AUTOSAR XML (schema 4-2-2)
package /STELLANTIS/EPT/ASWCs
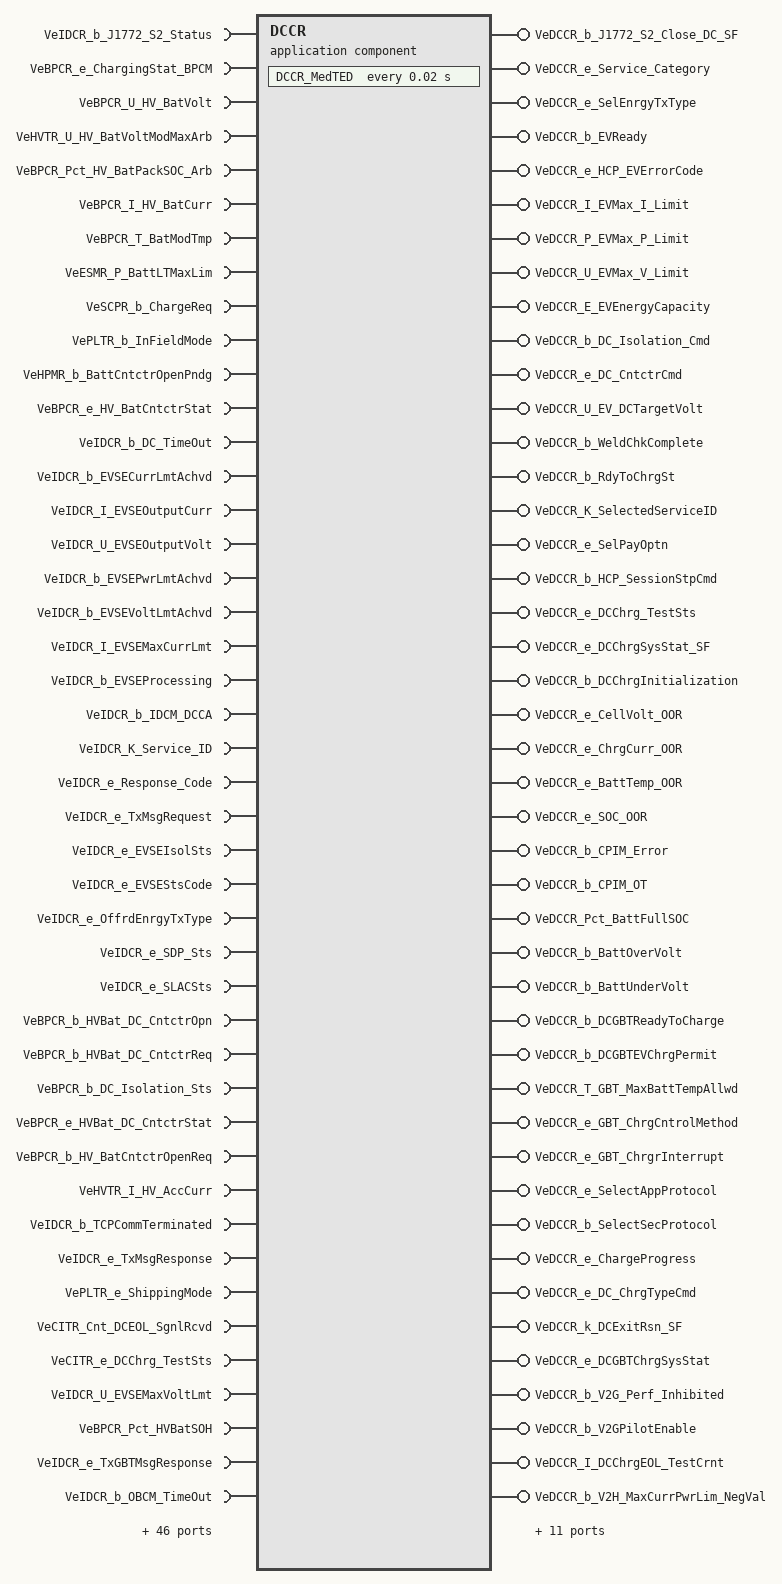
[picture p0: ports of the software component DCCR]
  application sw component type DCCR
    85 x require port:
      VeIDCR_b_J1772_S2_Status: variation-point={short-label=vpVeIDCR_b_J1772_S2_Status, sw-syscond=1}, nonqueued-receiver-com-spec{data-element=Value, init-value=0}, required-interface=VeIDCR_b_J1772_S2_Status
      VeBPCR_e_ChargingStat_BPCM: variation-point={short-label=vpVeBPCR_e_ChargingStat_BPCM, sw-syscond=1}, nonqueued-receiver-com-spec{data-element=Value, init-value=CeOBCR_e_BattNotReady}, required-interface=VeBPCR_e_ChargingStat_BPCM
      VeBPCR_U_HV_BatVolt: variation-point={short-label=vpVeBPCR_U_HV_BatVolt, sw-syscond=1}, nonqueued-receiver-com-spec{data-element=Value, init-value=0}, required-interface=VeBPCR_U_HV_BatVolt
      VeHVTR_U_HV_BatVoltModMaxArb: variation-point={short-label=vpVeHVTR_U_HV_BatVoltModMaxArb, sw-syscond=1}, nonqueued-receiver-com-spec{data-element=Value, init-value=0}, required-interface=VeHVTR_U_HV_BatVoltModMaxArb
      VeBPCR_Pct_HV_BatPackSOC_Arb: variation-point={short-label=vpVeBPCR_Pct_HV_BatPackSOC_Arb, sw-syscond=1}, nonqueued-receiver-com-spec{data-element=Value, init-value=0}, required-interface=VeBPCR_Pct_HV_BatPackSOC_Arb
      VeBPCR_I_HV_BatCurr: variation-point={short-label=vpVeBPCR_I_HV_BatCurr, sw-syscond=1}, nonqueued-receiver-com-spec{data-element=Value, init-value=0}, required-interface=VeBPCR_I_HV_BatCurr
      VeBPCR_T_BatModTmp: variation-point={short-label=vpVeBPCR_T_BatModTmp, sw-syscond=1}, nonqueued-receiver-com-spec{data-element=Value, init-value=0}, required-interface=VeBPCR_T_BatModTmp
      VeESMR_P_BattLTMaxLim: variation-point={short-label=vpVeESMR_P_BattLTMaxLim, sw-syscond=1}, nonqueued-receiver-com-spec{data-element=Value, init-value=0}, required-interface=VeESMR_P_BattLTMaxLim
      VeSCPR_b_ChargeReq: variation-point={short-label=vpVeSCPR_b_ChargeReq, sw-syscond=1}, nonqueued-receiver-com-spec{data-element=Value, init-value=0}, required-interface=VeSCPR_b_ChargeReq
      VePLTR_b_InFieldMode: variation-point={short-label=vpVePLTR_b_InFieldMode, sw-syscond=1}, nonqueued-receiver-com-spec{data-element=Value, init-value=0}, required-interface=VePLTR_b_InFieldMode
      VeHPMR_b_BattCntctrOpenPndg: variation-point={short-label=vpVeHPMR_b_BattCntctrOpenPndg, sw-syscond=1}, nonqueued-receiver-com-spec{data-element=Value, init-value=0}, required-interface=VeHPMR_b_BattCntctrOpenPndg
      VeBPCR_e_HV_BatCntctrStat: variation-point={short-label=vpVeBPCR_e_HV_BatCntctrStat, sw-syscond=1}, nonqueued-receiver-com-spec{data-element=Value, init-value=CeHVTR_e_Open}, required-interface=VeBPCR_e_HV_BatCntctrStat
      VeIDCR_b_DC_TimeOut: variation-point={short-label=vpVeIDCR_b_DC_TimeOut, sw-syscond=1}, nonqueued-receiver-com-spec{data-element=Value, init-value=0}, required-interface=VeIDCR_b_DC_TimeOut
      VeIDCR_b_EVSECurrLmtAchvd: variation-point={short-label=vpVeIDCR_b_EVSECurrLmtAchvd, sw-syscond=1}, nonqueued-receiver-com-spec{data-element=Value, init-value=0}, required-interface=VeIDCR_b_EVSECurrLmtAchvd
      VeIDCR_I_EVSEOutputCurr: variation-point={short-label=vpVeIDCR_I_EVSEOutputCurr, sw-syscond=1}, nonqueued-receiver-com-spec{data-element=Value, init-value=0}, required-interface=VeIDCR_I_EVSEOutputCurr
      VeIDCR_U_EVSEOutputVolt: variation-point={short-label=vpVeIDCR_U_EVSEOutputVolt, sw-syscond=1}, nonqueued-receiver-com-spec{data-element=Value, init-value=0}, required-interface=VeIDCR_U_EVSEOutputVolt
      VeIDCR_b_EVSEPwrLmtAchvd: variation-point={short-label=vpVeIDCR_b_EVSEPwrLmtAchvd, sw-syscond=1}, nonqueued-receiver-com-spec{data-element=Value, init-value=0}, required-interface=VeIDCR_b_EVSEPwrLmtAchvd
      VeIDCR_b_EVSEVoltLmtAchvd: variation-point={short-label=vpVeIDCR_b_EVSEVoltLmtAchvd, sw-syscond=1}, nonqueued-receiver-com-spec{data-element=Value, init-value=0}, required-interface=VeIDCR_b_EVSEVoltLmtAchvd
      VeIDCR_I_EVSEMaxCurrLmt: variation-point={short-label=vpVeIDCR_I_EVSEMaxCurrLmt, sw-syscond=1}, nonqueued-receiver-com-spec{data-element=Value, init-value=0}, required-interface=VeIDCR_I_EVSEMaxCurrLmt
      VeIDCR_b_EVSEProcessing: variation-point={short-label=vpVeIDCR_b_EVSEProcessing, sw-syscond=1}, nonqueued-receiver-com-spec{data-element=Value, init-value=0}, required-interface=VeIDCR_b_EVSEProcessing
      VeIDCR_b_IDCM_DCCA: variation-point={short-label=vpVeIDCR_b_IDCM_DCCA, sw-syscond=1}, nonqueued-receiver-com-spec{data-element=Value, init-value=0}, required-interface=VeIDCR_b_IDCM_DCCA
      VeIDCR_K_Service_ID: variation-point={short-label=vpVeIDCR_K_Service_ID, sw-syscond=1}, nonqueued-receiver-com-spec{data-element=Value, init-value=0}, required-interface=VeIDCR_K_Service_ID
      VeIDCR_e_Response_Code: variation-point={short-label=vpVeIDCR_e_Response_Code, sw-syscond=1}, nonqueued-receiver-com-spec{data-element=Value, init-value=CeIDCR_e_RC_OK}, required-interface=VeIDCR_e_Response_Code
      VeIDCR_e_TxMsgRequest: variation-point={short-label=vpVeIDCR_e_TxMsgRequest, sw-syscond=1}, nonqueued-receiver-com-spec{data-element=Value, init-value=CeIDCR_e_NoRequest}, required-interface=VeIDCR_e_TxMsgRequest
      VeIDCR_e_EVSEIsolSts: variation-point={short-label=vpVeIDCR_e_EVSEIsolSts, sw-syscond=1}, nonqueued-receiver-com-spec{data-element=Value, init-value=CeIDCR_e_EVSEIsolSts_Invalid}, required-interface=VeIDCR_e_EVSEIsolSts
      VeIDCR_e_EVSEStsCode: variation-point={short-label=vpVeIDCR_e_EVSEStsCode, sw-syscond=1}, nonqueued-receiver-com-spec{data-element=Value, init-value=CeIDCR_e_EVSEStsCode_No_Data}, required-interface=VeIDCR_e_EVSEStsCode
      VeIDCR_e_OffrdEnrgyTxType: variation-point={short-label=vpVeIDCR_e_OffrdEnrgyTxType, sw-syscond=1}, nonqueued-receiver-com-spec{data-element=Value, init-value=CeIDCR_e_EnrgyTxType_NoEnrgyTxType}, required-interface=VeIDCR_e_OffrdEnrgyTxType
      VeIDCR_e_SDP_Sts: variation-point={short-label=vpVeIDCR_e_SDP_Sts, sw-syscond=1}, nonqueued-receiver-com-spec{data-element=Value, init-value=CeIDCR_e_SDPSts_NoConnEst}, required-interface=VeIDCR_e_SDP_Sts
      VeIDCR_e_SLACSts: variation-point={short-label=vpVeIDCR_e_SLACSts, sw-syscond=1}, nonqueued-receiver-com-spec{data-element=Value, init-value=CeIDCR_e_SLACSts_EVSE_NtFnd}, required-interface=VeIDCR_e_SLACSts
      VeBPCR_b_HVBat_DC_CntctrOpn: variation-point={short-label=vpVeBPCR_b_HVBat_DC_CntctrOpn, sw-syscond=1}, nonqueued-receiver-com-spec{data-element=Value, init-value=0}, required-interface=VeBPCR_b_HVBat_DC_CntctrOpn
      VeBPCR_b_HVBat_DC_CntctrReq: variation-point={short-label=vpVeBPCR_b_HVBat_DC_CntctrReq, sw-syscond=1}, nonqueued-receiver-com-spec{data-element=Value, init-value=0}, required-interface=VeBPCR_b_HVBat_DC_CntctrReq
      VeBPCR_b_DC_Isolation_Sts: variation-point={short-label=vpVeBPCR_b_DC_Isolation_Sts, sw-syscond=1}, nonqueued-receiver-com-spec{data-element=Value, init-value=0}, required-interface=VeBPCR_b_DC_Isolation_Sts
      VeBPCR_e_HVBat_DC_CntctrStat: variation-point={short-label=vpVeBPCR_e_HVBat_DC_CntctrStat, sw-syscond=1}, nonqueued-receiver-com-spec{data-element=Value, init-value=CeBPCR_e_DCCntctrSts_Open}, required-interface=VeBPCR_e_HVBat_DC_CntctrStat
      VeBPCR_b_HV_BatCntctrOpenReq: variation-point={short-label=vpVeBPCR_b_HV_BatCntctrOpenReq, sw-syscond=1}, nonqueued-receiver-com-spec{data-element=Value, init-value=0}, required-interface=VeBPCR_b_HV_BatCntctrOpenReq
      VeHVTR_I_HV_AccCurr: variation-point={short-label=vpVeHVTR_I_HV_AccCurr, sw-syscond=1}, nonqueued-receiver-com-spec{data-element=Value, init-value=0}, required-interface=VeHVTR_I_HV_AccCurr
      VeIDCR_b_TCPCommTerminated: variation-point={short-label=vpVeIDCR_b_TCPCommTerminated, sw-syscond=1}, nonqueued-receiver-com-spec{data-element=Value, init-value=0}, required-interface=VeIDCR_b_TCPCommTerminated
      VeIDCR_e_TxMsgResponse: variation-point={short-label=vpVeIDCR_e_TxMsgResponse, sw-syscond=1}, nonqueued-receiver-com-spec{data-element=Value, init-value=CeIDCR_e_NoRequest}, required-interface=VeIDCR_e_TxMsgResponse
      VePLTR_e_ShippingMode: variation-point={short-label=vpVePLTR_e_ShippingMode, sw-syscond=1}, nonqueued-receiver-com-spec{data-element=Value, init-value=CePLTR_e_ShipingMode_CUST_MD}, required-interface=VePLTR_e_ShippingMode
      VeCITR_Cnt_DCEOL_SgnlRcvd: variation-point={short-label=vpVeCITR_Cnt_DCEOL_SgnlRcvd, sw-syscond=1}, nonqueued-receiver-com-spec{data-element=Value, init-value=0}, required-interface=VeCITR_Cnt_DCEOL_SgnlRcvd
      VeCITR_e_DCChrg_TestSts: variation-point={short-label=vpVeCITR_e_DCChrg_TestSts, sw-syscond=1}, nonqueued-receiver-com-spec{data-element=Value, init-value=CeOBCR_e_DCChrg_TestSts_NotInit}, required-interface=VeCITR_e_DCChrg_TestSts
      VeIDCR_U_EVSEMaxVoltLmt: variation-point={short-label=vpVeIDCR_U_EVSEMaxVoltLmt, sw-syscond=1}, nonqueued-receiver-com-spec{data-element=Value, init-value=0}, required-interface=VeIDCR_U_EVSEMaxVoltLmt
      VeBPCR_Pct_HVBatSOH: variation-point={short-label=vpVeBPCR_Pct_HVBatSOH, sw-syscond=1}, nonqueued-receiver-com-spec{data-element=Value, init-value=0}, required-interface=VeBPCR_Pct_HVBatSOH
      VeIDCR_e_TxGBTMsgResponse: variation-point={short-label=vpVeIDCR_e_TxGBTMsgResponse, sw-syscond=1}, nonqueued-receiver-com-spec{data-element=Value, init-value=CeIDCR_e_GBTRes_EVSE_Not_Connected}, required-interface=VeIDCR_e_TxGBTMsgResponse
      VeIDCR_b_OBCM_TimeOut: variation-point={short-label=vpVeIDCR_b_OBCM_TimeOut, sw-syscond=1}, nonqueued-receiver-com-spec{data-element=Value, init-value=0}, required-interface=VeIDCR_b_OBCM_TimeOut
      VeIDCR_e_Chrgr_FaultStates: variation-point={short-label=vpVeIDCR_e_Chrgr_FaultStates, sw-syscond=1}, nonqueued-receiver-com-spec{data-element=Value, init-value=CeIDCR_e_GBT_No_FLT}, required-interface=VeIDCR_e_Chrgr_FaultStates
      VeBPCR_b_StkOpnChkCmpl: variation-point={short-label=vpVeBPCR_b_StkOpnChkCmpl, sw-syscond=1}, nonqueued-receiver-com-spec{data-element=Value, init-value=0}, required-interface=VeBPCR_b_StkOpnChkCmpl
      VeIDCR_b_GBT_EVSEChrgPermitting: variation-point={short-label=vpVeIDCR_b_GBT_EVSEChrgPermitting, sw-syscond=1}, nonqueued-receiver-com-spec{data-element=Value, init-value=0}, required-interface=VeIDCR_b_GBT_EVSEChrgPermitting
      VeIDCR_e_OffrdPayOptn: variation-point={short-label=vpVeIDCR_e_OffrdPayOptn, sw-syscond=1}, nonqueued-receiver-com-spec{data-element=Value, init-value=CeIDCR_e_OffrdPayOptn_NoPaySel}, required-interface=VeIDCR_e_OffrdPayOptn
      VeIDCR_b_EVSE_FreeService: variation-point={short-label=vpVeIDCR_b_EVSE_FreeService, sw-syscond=1}, nonqueued-receiver-com-spec{data-element=Value, init-value=0}, required-interface=VeIDCR_b_EVSE_FreeService
      VeBPCR_e_DCIsolSts: variation-point={short-label=vpVeBPCR_e_DCIsolSts, sw-syscond=1}, nonqueued-receiver-com-spec{data-element=Value, init-value=CeBPCR_e_DCIsolSts_NotPerformed}, required-interface=VeBPCR_e_DCIsolSts
      VeIDCR_b_EVCC_FailureSts: variation-point={short-label=vpVeIDCR_b_EVCC_FailureSts, sw-syscond=1}, nonqueued-receiver-com-spec{data-element=Value, init-value=0}, required-interface=VeIDCR_b_EVCC_FailureSts
      VeIDCR_b_TLS_Offered: variation-point={short-label=vpVeIDCR_b_TLS_Offered, sw-syscond=1}, nonqueued-receiver-com-spec{data-element=Value, init-value=0}, required-interface=VeIDCR_b_TLS_Offered
      VeIDCR_e_TLS_Connection: variation-point={short-label=vpVeIDCR_e_TLS_Connection, sw-syscond=1}, nonqueued-receiver-com-spec{data-element=Value, init-value=CeIDCR_e_Not_Performed}, required-interface=VeIDCR_e_TLS_Connection
      VeIDCR_b_EVSEsupported_DIN: variation-point={short-label=vpVeIDCR_b_EVSEsupported_DIN, sw-syscond=1}, nonqueued-receiver-com-spec{data-element=Value, init-value=0}, required-interface=VeIDCR_b_EVSEsupported_DIN
      VeIDCR_e_EVSENotification: variation-point={short-label=vpVeIDCR_e_EVSENotification, sw-syscond=1}, nonqueued-receiver-com-spec{data-element=Value, init-value=CeIDCR_e_None}, required-interface=VeIDCR_e_EVSENotification
      VeIDCR_b_OfferedPaymentContract: variation-point={short-label=vpVeIDCR_b_OfferedPaymentContract, sw-syscond=1}, nonqueued-receiver-com-spec{data-element=Value, init-value=0}, required-interface=VeIDCR_b_OfferedPaymentContract
      VeIDCR_b_Service2_Certificate: variation-point={short-label=vpVeIDCR_b_Service2_Certificate, sw-syscond=1}, nonqueued-receiver-com-spec{data-element=Value, init-value=0}, required-interface=VeIDCR_b_Service2_Certificate
      VeIDCR_b_OfferedPaymentEIM: variation-point={short-label=vpVeIDCR_b_OfferedPaymentEIM, sw-syscond=1}, nonqueued-receiver-com-spec{data-element=Value, init-value=0}, required-interface=VeIDCR_b_OfferedPaymentEIM
      VeIDCR_e_PROXY_Plug_and_Charge: variation-point={short-label=vpVeIDCR_e_PROXY_Plug_and_Charge, sw-syscond=1}, nonqueued-receiver-com-spec{data-element=Value, init-value=CeIDCR_e_Absent}, required-interface=VeIDCR_e_PROXY_Plug_and_Charge
      VeIDCR_b_EVSEsupported_ISO1: variation-point={short-label=vpVeIDCR_b_EVSEsupported_ISO1, sw-syscond=1}, nonqueued-receiver-com-spec{data-element=Value, init-value=0}, required-interface=VeIDCR_b_EVSEsupported_ISO1
      VeHVTR_U_HvBattVolt_Arb: variation-point={short-label=vpVeHVTR_U_HvBattVolt_Arb, sw-syscond=1}, nonqueued-receiver-com-spec{data-element=Value, init-value=0}, required-interface=VeHVTR_U_HvBattVolt_Arb
      VeHVTR_I_StringsCurrFdbk: variation-point={short-label=vpVeHVTR_I_StringsCurrFdbk, sw-syscond=1}, nonqueued-receiver-com-spec{data-element=Value, init-value=0}, required-interface=VeHVTR_I_StringsCurrFdbk
      VeBPCR_e_HVDcChargeTypeStat: variation-point={short-label=vpVeBPCR_e_HVDcChargeTypeStat, sw-syscond=1}, nonqueued-receiver-com-spec{data-element=Value, init-value=CeBPCR_e_HVDcChargeStat_400V}, required-interface=VeBPCR_e_HVDcChargeTypeStat
      VeIDCR_I_EVSEMinCurrLmt: variation-point={short-label=vpVeIDCR_I_EVSEMinCurrLmt, sw-syscond=1}, nonqueued-receiver-com-spec{data-element=Value, init-value=0}, required-interface=VeIDCR_I_EVSEMinCurrLmt
      VeCPLR_b_Lock_Status: variation-point={short-label=vpVeCPLR_b_Lock_Status, sw-syscond=1}, nonqueued-receiver-com-spec{data-element=Value, init-value=0}, required-interface=VeCPLR_b_Lock_Status
      VeCCCR_I_ChrgCrntReqDelta: variation-point={short-label=vpVeCCCR_I_ChrgCrntReqDelta, sw-syscond=1}, nonqueued-receiver-com-spec{data-element=Value, init-value=0}, required-interface=VeCCCR_I_ChrgCrntReqDelta
      VeOBCR_b_PluggedIn: variation-point={short-label=vpVeOBCR_b_PluggedIn, sw-syscond=1}, nonqueued-receiver-com-spec{data-element=Value, init-value=0}, required-interface=VeOBCR_b_PluggedIn
      VeOBCR_b_EnableChargeDC: variation-point={short-label=vpVeOBCR_b_EnableChargeDC, sw-syscond=1}, nonqueued-receiver-com-spec{data-element=Value, init-value=0}, required-interface=VeOBCR_b_EnableChargeDC
      VeOBCR_e_ChrgSysStat_SF: variation-point={short-label=vpVeOBCR_e_ChrgSysStat_SF, sw-syscond=1}, nonqueued-receiver-com-spec{data-element=Value, init-value=CeOBCR_e_PowerUp}, required-interface=VeOBCR_e_ChrgSysStat_SF
      VeOBCR_b_ChargingComplete: variation-point={short-label=vpVeOBCR_b_ChargingComplete, sw-syscond=1}, nonqueued-receiver-com-spec{data-element=Value, init-value=0}, required-interface=VeOBCR_b_ChargingComplete
      VeOBCR_e_ChargeType: variation-point={short-label=vpVeOBCR_e_ChargeType, sw-syscond=1}, nonqueued-receiver-com-spec{data-element=Value, init-value=CeOBCR_e_AC}, required-interface=VeOBCR_e_ChargeType
      VeOBCR_b_EnblDC_GBT: variation-point={short-label=vpVeOBCR_b_EnblDC_GBT, sw-syscond=1}, nonqueued-receiver-com-spec{data-element=Value, init-value=0}, required-interface=VeOBCR_b_EnblDC_GBT
      VeIDCR_b_V2X_EVSE_Service_5_Free: variation-point={short-label=vpVeIDCR_b_V2X_EVSE_Service_5_Free, sw-syscond=1}, nonqueued-receiver-com-spec{data-element=Value, init-value=0}, required-interface=VeIDCR_b_V2X_EVSE_Service_5_Free
      VeIDCR_b_V2X_EVSE_Service_5_V2H: variation-point={short-label=vpVeIDCR_b_V2X_EVSE_Service_5_V2H, sw-syscond=1}, nonqueued-receiver-com-spec{data-element=Value, init-value=0}, required-interface=VeIDCR_b_V2X_EVSE_Service_5_V2H
      VeVTHR_b_V2H_Detected: variation-point={short-label=vpVeVTHR_b_V2H_Detected, sw-syscond=1}, nonqueued-receiver-com-spec{data-element=Value, init-value=0}, required-interface=VeVTHR_b_V2H_Detected
      VeVTHR_b_Rdy4shutdown: variation-point={short-label=vpVeVTHR_b_Rdy4shutdown, sw-syscond=1}, nonqueued-receiver-com-spec{data-element=Value, init-value=0}, required-interface=VeVTHR_b_Rdy4shutdown
      VeIDCR_b_PlugAndChargeReq: variation-point={short-label=vpVeIDCR_b_PlugAndChargeReq, sw-syscond=1}, nonqueued-receiver-com-spec{data-element=Value, init-value=0}, required-interface=VeIDCR_b_PlugAndChargeReq
      VeIDCR_b_ISO15118_TLS_Offered: variation-point={short-label=vpVeIDCR_b_ISO15118_TLS_Offered, sw-syscond=1}, nonqueued-receiver-com-spec{data-element=Value, init-value=0}, required-interface=VeIDCR_b_ISO15118_TLS_Offered
      VeIDCR_b_EVSE_Offered_DC_Extended: variation-point={short-label=vpVeIDCR_b_EVSE_Offered_DC_Extended, sw-syscond=1}, nonqueued-receiver-com-spec{data-element=Value, init-value=0}, required-interface=VeIDCR_b_EVSE_Offered_DC_Extended
      VeIDCR_b_EVSE_Service1_Free: variation-point={short-label=vpVeIDCR_b_EVSE_Service1_Free, sw-syscond=1}, nonqueued-receiver-com-spec{data-element=Value, init-value=0}, required-interface=VeIDCR_b_EVSE_Service1_Free
      VeIDCR_b_EVSE_Service1_Charging: variation-point={short-label=vpVeIDCR_b_EVSE_Service1_Charging, sw-syscond=1}, nonqueued-receiver-com-spec{data-element=Value, init-value=0}, required-interface=VeIDCR_b_EVSE_Service1_Charging
      VeIDCR_t_ISO15118_NotificationMaxDelay: variation-point={short-label=vpVeIDCR_t_ISO15118_NotificationMaxDelay, sw-syscond=1}, nonqueued-receiver-com-spec{data-element=Value, init-value=0}, required-interface=VeIDCR_t_ISO15118_NotificationMaxDelay
      VeIDCR_e_ISO15118_ResponseCode: variation-point={short-label=vpVeIDCR_e_ISO15118_ResponseCode, sw-syscond=1}, nonqueued-receiver-com-spec{data-element=Value, init-value=CeIDCR_e_OK}, required-interface=VeIDCR_e_ISO15118_ResponseCode
      VeIDCR_e_ISO15118_TLS_Status: variation-point={short-label=vpVeIDCR_e_ISO15118_TLS_Status, sw-syscond=1}, nonqueued-receiver-com-spec{data-element=Value, init-value=CeIDCR_e_Not_Performed}, required-interface=VeIDCR_e_ISO15118_TLS_Status
      VeIDCR_P_EVSEMaxPwrLmt: variation-point={short-label=vpVeIDCR_P_EVSEMaxPwrLmt, sw-syscond=1}, nonqueued-receiver-com-spec{data-element=Value, init-value=0}, required-interface=VeIDCR_P_EVSEMaxPwrLmt
    52 x provide port:
      VeDCCR_b_J1772_S2_Close_DC_SF: nonqueued-sender-com-spec{data-element=Value, init-value=0}, provided-interface=VeDCCR_b_J1772_S2_Close_DC_SF
      VeDCCR_e_Service_Category: nonqueued-sender-com-spec{data-element=Value, init-value=0}, provided-interface=VeDCCR_e_Service_Category
      VeDCCR_e_SelEnrgyTxType: nonqueued-sender-com-spec{data-element=Value, init-value=0}, provided-interface=VeDCCR_e_SelEnrgyTxType
      VeDCCR_b_EVReady: nonqueued-sender-com-spec{data-element=Value, init-value=0}, provided-interface=VeDCCR_b_EVReady
      VeDCCR_e_HCP_EVErrorCode: nonqueued-sender-com-spec{data-element=Value, init-value=0}, provided-interface=VeDCCR_e_HCP_EVErrorCode
      VeDCCR_I_EVMax_I_Limit: nonqueued-sender-com-spec{data-element=Value, init-value=0}, provided-interface=VeDCCR_I_EVMax_I_Limit
      VeDCCR_P_EVMax_P_Limit: nonqueued-sender-com-spec{data-element=Value, init-value=0}, provided-interface=VeDCCR_P_EVMax_P_Limit
      VeDCCR_U_EVMax_V_Limit: nonqueued-sender-com-spec{data-element=Value, init-value=0}, provided-interface=VeDCCR_U_EVMax_V_Limit
      VeDCCR_E_EVEnergyCapacity: nonqueued-sender-com-spec{data-element=Value, init-value=0}, provided-interface=VeDCCR_E_EVEnergyCapacity
      VeDCCR_b_DC_Isolation_Cmd: nonqueued-sender-com-spec{data-element=Value, init-value=0}, provided-interface=VeDCCR_b_DC_Isolation_Cmd
      VeDCCR_e_DC_CntctrCmd: nonqueued-sender-com-spec{data-element=Value, init-value=CeOBCR_e_DCCntctr_Open}, provided-interface=VeDCCR_e_DC_CntctrCmd
      VeDCCR_U_EV_DCTargetVolt: nonqueued-sender-com-spec{data-element=Value, init-value=0}, provided-interface=VeDCCR_U_EV_DCTargetVolt
      VeDCCR_b_WeldChkComplete: nonqueued-sender-com-spec{data-element=Value, init-value=0}, provided-interface=VeDCCR_b_WeldChkComplete
      VeDCCR_b_RdyToChrgSt: nonqueued-sender-com-spec{data-element=Value, init-value=0}, provided-interface=VeDCCR_b_RdyToChrgSt
      VeDCCR_K_SelectedServiceID: nonqueued-sender-com-spec{data-element=Value, init-value=0}, provided-interface=VeDCCR_K_SelectedServiceID
      VeDCCR_e_SelPayOptn: nonqueued-sender-com-spec{data-element=Value, init-value=CeOBCR_e_NoPaymentSel}, provided-interface=VeDCCR_e_SelPayOptn
      VeDCCR_b_HCP_SessionStpCmd: nonqueued-sender-com-spec{data-element=Value, init-value=0}, provided-interface=VeDCCR_b_HCP_SessionStpCmd
      VeDCCR_e_DCChrg_TestSts: nonqueued-sender-com-spec{data-element=Value, init-value=CeOBCR_e_DCChrg_TestSts_NotInit}, provided-interface=VeDCCR_e_DCChrg_TestSts
      VeDCCR_e_DCChrgSysStat_SF: nonqueued-sender-com-spec{data-element=Value, init-value=CeOBCR_e_DCinit}, provided-interface=VeDCCR_e_DCChrgSysStat_SF
      VeDCCR_b_DCChrgInitialization: nonqueued-sender-com-spec{data-element=Value, init-value=0}, provided-interface=VeDCCR_b_DCChrgInitialization
      VeDCCR_e_CellVolt_OOR: nonqueued-sender-com-spec{data-element=Value, init-value=CeOBCR_e_CellVoltStat_Normal}, provided-interface=VeDCCR_e_CellVolt_OOR
      VeDCCR_e_ChrgCurr_OOR: nonqueued-sender-com-spec{data-element=Value, init-value=CeOBCR_e_ChrgCurrStat_Normal}, provided-interface=VeDCCR_e_ChrgCurr_OOR
      VeDCCR_e_BattTemp_OOR: nonqueued-sender-com-spec{data-element=Value, init-value=CeOBCR_e_BattTempStat_Normal}, provided-interface=VeDCCR_e_BattTemp_OOR
      VeDCCR_e_SOC_OOR: nonqueued-sender-com-spec{data-element=Value, init-value=CeOBCR_e_BattSOCStat_Normal}, provided-interface=VeDCCR_e_SOC_OOR
      VeDCCR_b_CPIM_Error: nonqueued-sender-com-spec{data-element=Value, init-value=0}, provided-interface=VeDCCR_b_CPIM_Error
      VeDCCR_b_CPIM_OT: nonqueued-sender-com-spec{data-element=Value, init-value=0}, provided-interface=VeDCCR_b_CPIM_OT
      VeDCCR_Pct_BattFullSOC: nonqueued-sender-com-spec{data-element=Value, init-value=0}, provided-interface=VeDCCR_Pct_BattFullSOC
      VeDCCR_b_BattOverVolt: nonqueued-sender-com-spec{data-element=Value, init-value=0}, provided-interface=VeDCCR_b_BattOverVolt
      VeDCCR_b_BattUnderVolt: nonqueued-sender-com-spec{data-element=Value, init-value=0}, provided-interface=VeDCCR_b_BattUnderVolt
      VeDCCR_b_DCGBTReadyToCharge: nonqueued-sender-com-spec{data-element=Value, init-value=0}, provided-interface=VeDCCR_b_DCGBTReadyToCharge
      VeDCCR_b_DCGBTEVChrgPermit: nonqueued-sender-com-spec{data-element=Value, init-value=0}, provided-interface=VeDCCR_b_DCGBTEVChrgPermit
      VeDCCR_T_GBT_MaxBattTempAllwd: nonqueued-sender-com-spec{data-element=Value, init-value=0}, provided-interface=VeDCCR_T_GBT_MaxBattTempAllwd
      VeDCCR_e_GBT_ChrgCntrolMethod: nonqueued-sender-com-spec{data-element=Value, init-value=CeOBCR_e_ChrgMthd_Init}, provided-interface=VeDCCR_e_GBT_ChrgCntrolMethod
      VeDCCR_e_GBT_ChrgrInterrupt: nonqueued-sender-com-spec{data-element=Value, init-value=CeOBCR_e_NoChrgrInterrupt}, provided-interface=VeDCCR_e_GBT_ChrgrInterrupt
      VeDCCR_e_SelectAppProtocol: nonqueued-sender-com-spec{data-element=Value, init-value=CeOBCR_e_DIN}, provided-interface=VeDCCR_e_SelectAppProtocol
      VeDCCR_b_SelectSecProtocol: nonqueued-sender-com-spec{data-element=Value, init-value=0}, provided-interface=VeDCCR_b_SelectSecProtocol
      VeDCCR_e_ChargeProgress: nonqueued-sender-com-spec{data-element=Value, init-value=CeOBCR_e_No_Request}, provided-interface=VeDCCR_e_ChargeProgress
      VeDCCR_e_DC_ChrgTypeCmd: nonqueued-sender-com-spec{data-element=Value, init-value=CeOBCR_e_DC_ChrgType_Null}, provided-interface=VeDCCR_e_DC_ChrgTypeCmd
      VeDCCR_k_DCExitRsn_SF: nonqueued-sender-com-spec{data-element=Value, init-value=0}, provided-interface=VeDCCR_k_DCExitRsn_SF
      VeDCCR_e_DCGBTChrgSysStat: nonqueued-sender-com-spec{data-element=Value, init-value=CeOBCR_e_DCGBTinit}, provided-interface=VeDCCR_e_DCGBTChrgSysStat
      VeDCCR_b_V2G_Perf_Inhibited: nonqueued-sender-com-spec{data-element=Value, init-value=0}, provided-interface=VeDCCR_b_V2G_Perf_Inhibited
      VeDCCR_b_V2GPilotEnable: nonqueued-sender-com-spec{data-element=Value, init-value=0}, provided-interface=VeDCCR_b_V2GPilotEnable
      VeDCCR_I_DCChrgEOL_TestCrnt: nonqueued-sender-com-spec{data-element=Value, init-value=0}, provided-interface=VeDCCR_I_DCChrgEOL_TestCrnt
      VeDCCR_b_V2H_MaxCurrPwrLim_NegVal: nonqueued-sender-com-spec{data-element=Value, init-value=0}, provided-interface=VeDCCR_b_V2H_MaxCurrPwrLim_NegVal
      VeDCCR_b_V2H_SelEnergyTransType: nonqueued-sender-com-spec{data-element=Value, init-value=0}, provided-interface=VeDCCR_b_V2H_SelEnergyTransType
      VeDCCR_P_V2H_EVMaxPwrLim: nonqueued-sender-com-spec{data-element=Value, init-value=0}, provided-interface=VeDCCR_P_V2H_EVMaxPwrLim
      VeDCCR_e_Protocol_Priority{1..3}: nonqueued-sender-com-spec{data-element=Value, init-value=CeOBCR_e_No_Protocol}, provided-interface=VeDCCR_e_Protocol_Priority{1..3}
      VeDCCR_k_MaxEntriesSASScheduleTuple: nonqueued-sender-com-spec{data-element=Value, init-value=0}, provided-interface=VeDCCR_k_MaxEntriesSASScheduleTuple
      VeDCCR_b_PnCFailure: nonqueued-sender-com-spec{data-element=Value, init-value=0}, provided-interface=VeDCCR_b_PnCFailure
      VeDCCR_b_PnCRetryFail: nonqueued-sender-com-spec{data-element=Value, init-value=0}, provided-interface=VeDCCR_b_PnCRetryFail
    5 x require port:
      EeDCCR_t_V2GPerfInhibTime_Rx: variation-point={short-label=vpEeDCCR_t_V2GPerfInhibTime_Rx, sw-syscond=1}, nv-require-com-spec{init-value=0, variable=EeDCCR_t_V2GPerfInhibTime}, required-interface=EeDCCR_t_V2GPerfInhibTime
      EeDCCR_t_V2GTime_Rx: variation-point={short-label=vpEeDCCR_t_V2GTime_Rx, sw-syscond=1}, nv-require-com-spec{init-value=0, variable=EeDCCR_t_V2GTime}, required-interface=EeDCCR_t_V2GTime
      NeDCCR_E_TECharge_Rx: variation-point={short-label=vpNeDCCR_E_TECharge_Rx, sw-syscond=1}, nv-require-com-spec{init-value=0, variable=NeDCCR_E_TECharge}, required-interface=NeDCCR_E_TECharge
      NeDCCR_E_TEDischarge_Rx: variation-point={short-label=vpNeDCCR_E_TEDischarge_Rx, sw-syscond=1}, nv-require-com-spec{init-value=0, variable=NeDCCR_E_TEDischarge}, required-interface=NeDCCR_E_TEDischarge
      AeDCCR_y_DCChrgTestSts_Rx: variation-point={short-label=vpAeDCCR_y_DCChrgTestSts_Rx, sw-syscond=1}, nv-require-com-spec{init-value=0, variable=AeDCCR_y_DCChrgTestSts}, required-interface=AeDCCR_y_DCChrgTestSts
    5 x provide port:
      EeDCCR_t_V2GPerfInhibTime: variation-point={short-label=vpEeDCCR_t_V2GPerfInhibTime, sw-syscond=1}, nv-provide-com-spec{ram-block-init-value=0, variable=EeDCCR_t_V2GPerfInhibTime}, provided-interface=EeDCCR_t_V2GPerfInhibTime
      EeDCCR_t_V2GTime: variation-point={short-label=vpEeDCCR_t_V2GTime, sw-syscond=1}, nv-provide-com-spec{ram-block-init-value=0, variable=EeDCCR_t_V2GTime}, provided-interface=EeDCCR_t_V2GTime
      NeDCCR_E_TECharge: variation-point={short-label=vpNeDCCR_E_TECharge, sw-syscond=1}, nv-provide-com-spec{ram-block-init-value=0, variable=NeDCCR_E_TECharge}, provided-interface=NeDCCR_E_TECharge
      NeDCCR_E_TEDischarge: variation-point={short-label=vpNeDCCR_E_TEDischarge, sw-syscond=1}, nv-provide-com-spec{ram-block-init-value=0, variable=NeDCCR_E_TEDischarge}, provided-interface=NeDCCR_E_TEDischarge
      AeDCCR_y_DCChrgTestSts: variation-point={short-label=vpAeDCCR_y_DCChrgTestSts, sw-syscond=1}, nv-provide-com-spec{ram-block-init-value=0, variable=AeDCCR_y_DCChrgTestSts}, provided-interface=AeDCCR_y_DCChrgTestSts
    behavior IB_DCCR: data-type-mapping=msADTtoIDTMapping, handle-termination-and-restart=NO-SUPPORT
      timing event Event_MedTED: start-on-event=DCCR_MedTED, period=0.02
      init event Event_DCCR_ac_Init: start-on-event=DCCR_ac_Init
      init event Event_PwrOn: start-on-event=DCCR_PwrOn
      init event Event_PwrOff: start-on-event=DCCR_PwrOff
      4 x runnable:
        DCCR_ac_Init
          data-send-points:
            17 x access:
              OUT_VeDCCR_e_DC_CntctrCmd_Value: accessed-variable=VeDCCR_e_DC_CntctrCmd.Value
              OUT_VeDCCR_e_SelPayOptn_Value: accessed-variable=VeDCCR_e_SelPayOptn.Value
              OUT_VeDCCR_e_DCChrg_TestSts_Value: accessed-variable=VeDCCR_e_DCChrg_TestSts.Value
              OUT_VeDCCR_e_DCChrgSysStat_SF_Value: accessed-variable=VeDCCR_e_DCChrgSysStat_SF.Value
              OUT_VeDCCR_e_CellVolt_OOR_Value: accessed-variable=VeDCCR_e_CellVolt_OOR.Value
              OUT_VeDCCR_e_ChrgCurr_OOR_Value: accessed-variable=VeDCCR_e_ChrgCurr_OOR.Value
              OUT_VeDCCR_e_BattTemp_OOR_Value: accessed-variable=VeDCCR_e_BattTemp_OOR.Value
              OUT_VeDCCR_e_SOC_OOR_Value: accessed-variable=VeDCCR_e_SOC_OOR.Value
              OUT_VeDCCR_e_GBT_ChrgCntrolMethod_Value: accessed-variable=VeDCCR_e_GBT_ChrgCntrolMethod.Value
              OUT_VeDCCR_e_GBT_ChrgrInterrupt_Value: accessed-variable=VeDCCR_e_GBT_ChrgrInterrupt.Value
              OUT_VeDCCR_e_SelectAppProtocol_Value: accessed-variable=VeDCCR_e_SelectAppProtocol.Value
              OUT_VeDCCR_e_ChargeProgress_Value: accessed-variable=VeDCCR_e_ChargeProgress.Value
              OUT_VeDCCR_e_DC_ChrgTypeCmd_Value: accessed-variable=VeDCCR_e_DC_ChrgTypeCmd.Value
              OUT_VeDCCR_e_DCGBTChrgSysStat_Value: accessed-variable=VeDCCR_e_DCGBTChrgSysStat.Value
              OUT_VeDCCR_e_Protocol_Priority{1..3}_Value: accessed-variable=VeDCCR_e_Protocol_Priority{1..3}.Value
        DCCR_PwrOn
          data-receive-point-by-arguments:
            5 x access:
              IN_AeDCCR_y_DCChrgTestSts_Rx_AeDCCR_y_DCChrgTestSts: accessed-variable=AeDCCR_y_DCChrgTestSts_Rx.AeDCCR_y_DCChrgTestSts, variation-point={short-label=vpIN_AeDCCR_y_DCChrgTestSts_Rx_AeDCCR_y_DCChrgTestSts, sw-syscond=1}
              IN_EeDCCR_t_V2GPerfInhibTime_Rx_EeDCCR_t_V2GPerfInhibTime: accessed-variable=EeDCCR_t_V2GPerfInhibTime_Rx.EeDCCR_t_V2GPerfInhibTime, variation-point={short-label=vpIN_EeDCCR_t_V2GPerfInhibTime_Rx_EeDCCR_t_V2GPerfInhibTime, sw-syscond=1}
              IN_EeDCCR_t_V2GTime_Rx_EeDCCR_t_V2GTime: accessed-variable=EeDCCR_t_V2GTime_Rx.EeDCCR_t_V2GTime, variation-point={short-label=vpIN_EeDCCR_t_V2GTime_Rx_EeDCCR_t_V2GTime, sw-syscond=1}
              IN_NeDCCR_E_TECharge_Rx_NeDCCR_E_TECharge: accessed-variable=NeDCCR_E_TECharge_Rx.NeDCCR_E_TECharge, variation-point={short-label=vpIN_NeDCCR_E_TECharge_Rx_NeDCCR_E_TECharge, sw-syscond=1}
              IN_NeDCCR_E_TEDischarge_Rx_NeDCCR_E_TEDischarge: accessed-variable=NeDCCR_E_TEDischarge_Rx.NeDCCR_E_TEDischarge, variation-point={short-label=vpIN_NeDCCR_E_TEDischarge_Rx_NeDCCR_E_TEDischarge, sw-syscond=1}
          data-send-points:
            52 x access:
              OUT_VeDCCR_b_J1772_S2_Close_DC_SF_Value: accessed-variable=VeDCCR_b_J1772_S2_Close_DC_SF.Value
              OUT_VeDCCR_e_Service_Category_Value: accessed-variable=VeDCCR_e_Service_Category.Value
              OUT_VeDCCR_e_SelEnrgyTxType_Value: accessed-variable=VeDCCR_e_SelEnrgyTxType.Value
              OUT_VeDCCR_b_EVReady_Value: accessed-variable=VeDCCR_b_EVReady.Value
              OUT_VeDCCR_e_HCP_EVErrorCode_Value: accessed-variable=VeDCCR_e_HCP_EVErrorCode.Value
              OUT_VeDCCR_I_EVMax_I_Limit_Value: accessed-variable=VeDCCR_I_EVMax_I_Limit.Value
              OUT_VeDCCR_P_EVMax_P_Limit_Value: accessed-variable=VeDCCR_P_EVMax_P_Limit.Value
              OUT_VeDCCR_U_EVMax_V_Limit_Value: accessed-variable=VeDCCR_U_EVMax_V_Limit.Value
              OUT_VeDCCR_b_DC_Isolation_Cmd_Value: accessed-variable=VeDCCR_b_DC_Isolation_Cmd.Value
              OUT_VeDCCR_e_DC_CntctrCmd_Value: accessed-variable=VeDCCR_e_DC_CntctrCmd.Value
              OUT_VeDCCR_U_EV_DCTargetVolt_Value: accessed-variable=VeDCCR_U_EV_DCTargetVolt.Value
              OUT_VeDCCR_b_WeldChkComplete_Value: accessed-variable=VeDCCR_b_WeldChkComplete.Value
              OUT_VeDCCR_b_RdyToChrgSt_Value: accessed-variable=VeDCCR_b_RdyToChrgSt.Value
              OUT_VeDCCR_K_SelectedServiceID_Value: accessed-variable=VeDCCR_K_SelectedServiceID.Value
              OUT_VeDCCR_e_SelPayOptn_Value: accessed-variable=VeDCCR_e_SelPayOptn.Value
              OUT_VeDCCR_b_HCP_SessionStpCmd_Value: accessed-variable=VeDCCR_b_HCP_SessionStpCmd.Value
              OUT_VeDCCR_e_DCChrgSysStat_SF_Value: accessed-variable=VeDCCR_e_DCChrgSysStat_SF.Value
              OUT_VeDCCR_e_DCChrg_TestSts_Value: accessed-variable=VeDCCR_e_DCChrg_TestSts.Value
              OUT_VeDCCR_b_DCChrgInitialization_Value: accessed-variable=VeDCCR_b_DCChrgInitialization.Value
              OUT_VeDCCR_e_CellVolt_OOR_Value: accessed-variable=VeDCCR_e_CellVolt_OOR.Value
              OUT_VeDCCR_e_ChrgCurr_OOR_Value: accessed-variable=VeDCCR_e_ChrgCurr_OOR.Value
              OUT_VeDCCR_e_BattTemp_OOR_Value: accessed-variable=VeDCCR_e_BattTemp_OOR.Value
              OUT_VeDCCR_e_SOC_OOR_Value: accessed-variable=VeDCCR_e_SOC_OOR.Value
              OUT_VeDCCR_b_CPIM_Error_Value: accessed-variable=VeDCCR_b_CPIM_Error.Value
              OUT_VeDCCR_b_CPIM_OT_Value: accessed-variable=VeDCCR_b_CPIM_OT.Value
              OUT_VeDCCR_Pct_BattFullSOC_Value: accessed-variable=VeDCCR_Pct_BattFullSOC.Value
              OUT_VeDCCR_b_BattOverVolt_Value: accessed-variable=VeDCCR_b_BattOverVolt.Value
              OUT_VeDCCR_b_BattUnderVolt_Value: accessed-variable=VeDCCR_b_BattUnderVolt.Value
              OUT_VeDCCR_b_DCGBTReadyToCharge_Value: accessed-variable=VeDCCR_b_DCGBTReadyToCharge.Value
              OUT_VeDCCR_b_DCGBTEVChrgPermit_Value: accessed-variable=VeDCCR_b_DCGBTEVChrgPermit.Value
              OUT_VeDCCR_T_GBT_MaxBattTempAllwd_Value: accessed-variable=VeDCCR_T_GBT_MaxBattTempAllwd.Value
              OUT_VeDCCR_e_GBT_ChrgCntrolMethod_Value: accessed-variable=VeDCCR_e_GBT_ChrgCntrolMethod.Value
              OUT_VeDCCR_e_GBT_ChrgrInterrupt_Value: accessed-variable=VeDCCR_e_GBT_ChrgrInterrupt.Value
              OUT_VeDCCR_e_SelectAppProtocol_Value: accessed-variable=VeDCCR_e_SelectAppProtocol.Value
              OUT_VeDCCR_b_SelectSecProtocol_Value: accessed-variable=VeDCCR_b_SelectSecProtocol.Value
              OUT_VeDCCR_e_ChargeProgress_Value: accessed-variable=VeDCCR_e_ChargeProgress.Value
              OUT_VeDCCR_e_DC_ChrgTypeCmd_Value: accessed-variable=VeDCCR_e_DC_ChrgTypeCmd.Value
              OUT_VeDCCR_k_DCExitRsn_SF_Value: accessed-variable=VeDCCR_k_DCExitRsn_SF.Value
              OUT_VeDCCR_e_DCGBTChrgSysStat_Value: accessed-variable=VeDCCR_e_DCGBTChrgSysStat.Value
              OUT_VeDCCR_b_V2G_Perf_Inhibited_Value: accessed-variable=VeDCCR_b_V2G_Perf_Inhibited.Value
              OUT_VeDCCR_b_V2GPilotEnable_Value: accessed-variable=VeDCCR_b_V2GPilotEnable.Value
              OUT_VeDCCR_I_DCChrgEOL_TestCrnt_Value: accessed-variable=VeDCCR_I_DCChrgEOL_TestCrnt.Value
              OUT_VeDCCR_E_EVEnergyCapacity_Value: accessed-variable=VeDCCR_E_EVEnergyCapacity.Value
              OUT_VeDCCR_b_V2H_MaxCurrPwrLim_NegVal_Value: accessed-variable=VeDCCR_b_V2H_MaxCurrPwrLim_NegVal.Value
              OUT_VeDCCR_b_V2H_SelEnergyTransType_Value: accessed-variable=VeDCCR_b_V2H_SelEnergyTransType.Value
              OUT_VeDCCR_P_V2H_EVMaxPwrLim_Value: accessed-variable=VeDCCR_P_V2H_EVMaxPwrLim.Value
              OUT_VeDCCR_e_Protocol_Priority{1..3}_Value: accessed-variable=VeDCCR_e_Protocol_Priority{1..3}.Value
              OUT_VeDCCR_k_MaxEntriesSASScheduleTuple_Value: accessed-variable=VeDCCR_k_MaxEntriesSASScheduleTuple.Value
              OUT_VeDCCR_b_PnCFailure_Value: accessed-variable=VeDCCR_b_PnCFailure.Value
              OUT_VeDCCR_b_PnCRetryFail_Value: accessed-variable=VeDCCR_b_PnCRetryFail.Value
        DCCR_MedTED: variation-point={short-label=vpDCCR_MedTED, sw-syscond=1}
          data-receive-point-by-arguments:
            85 x access:
              IN_VeBPCR_I_HV_BatCurr_Value: accessed-variable=VeBPCR_I_HV_BatCurr.Value, variation-point={short-label=vpIN_VeBPCR_I_HV_BatCurr_Value, sw-syscond=1}
              IN_VeBPCR_Pct_HVBatSOH_Value: accessed-variable=VeBPCR_Pct_HVBatSOH.Value, variation-point={short-label=vpIN_VeBPCR_Pct_HVBatSOH_Value, sw-syscond=1}
              IN_VeBPCR_Pct_HV_BatPackSOC_Arb_Value: accessed-variable=VeBPCR_Pct_HV_BatPackSOC_Arb.Value, variation-point={short-label=vpIN_VeBPCR_Pct_HV_BatPackSOC_Arb_Value, sw-syscond=1}
              IN_VeBPCR_T_BatModTmp_Value: accessed-variable=VeBPCR_T_BatModTmp.Value, variation-point={short-label=vpIN_VeBPCR_T_BatModTmp_Value, sw-syscond=1}
              IN_VeBPCR_U_HV_BatVolt_Value: accessed-variable=VeBPCR_U_HV_BatVolt.Value, variation-point={short-label=vpIN_VeBPCR_U_HV_BatVolt_Value, sw-syscond=1}
              IN_VeBPCR_b_DC_Isolation_Sts_Value: accessed-variable=VeBPCR_b_DC_Isolation_Sts.Value, variation-point={short-label=vpIN_VeBPCR_b_DC_Isolation_Sts_Value, sw-syscond=1}
              IN_VeBPCR_b_HVBat_DC_CntctrOpn_Value: accessed-variable=VeBPCR_b_HVBat_DC_CntctrOpn.Value, variation-point={short-label=vpIN_VeBPCR_b_HVBat_DC_CntctrOpn_Value, sw-syscond=1}
              IN_VeBPCR_b_HVBat_DC_CntctrReq_Value: accessed-variable=VeBPCR_b_HVBat_DC_CntctrReq.Value, variation-point={short-label=vpIN_VeBPCR_b_HVBat_DC_CntctrReq_Value, sw-syscond=1}
              IN_VeBPCR_b_HV_BatCntctrOpenReq_Value: accessed-variable=VeBPCR_b_HV_BatCntctrOpenReq.Value, variation-point={short-label=vpIN_VeBPCR_b_HV_BatCntctrOpenReq_Value, sw-syscond=1}
              IN_VeBPCR_b_StkOpnChkCmpl_Value: accessed-variable=VeBPCR_b_StkOpnChkCmpl.Value, variation-point={short-label=vpIN_VeBPCR_b_StkOpnChkCmpl_Value, sw-syscond=1}
              IN_VeBPCR_e_ChargingStat_BPCM_Value: accessed-variable=VeBPCR_e_ChargingStat_BPCM.Value, variation-point={short-label=vpIN_VeBPCR_e_ChargingStat_BPCM_Value, sw-syscond=1}
              IN_VeBPCR_e_DCIsolSts_Value: accessed-variable=VeBPCR_e_DCIsolSts.Value, variation-point={short-label=vpIN_VeBPCR_e_DCIsolSts_Value, sw-syscond=1}
              IN_VeBPCR_e_HVBat_DC_CntctrStat_Value: accessed-variable=VeBPCR_e_HVBat_DC_CntctrStat.Value, variation-point={short-label=vpIN_VeBPCR_e_HVBat_DC_CntctrStat_Value, sw-syscond=1}
              IN_VeBPCR_e_HVDcChargeTypeStat_Value: accessed-variable=VeBPCR_e_HVDcChargeTypeStat.Value, variation-point={short-label=vpIN_VeBPCR_e_HVDcChargeTypeStat_Value, sw-syscond=1}
              IN_VeBPCR_e_HV_BatCntctrStat_Value: accessed-variable=VeBPCR_e_HV_BatCntctrStat.Value, variation-point={short-label=vpIN_VeBPCR_e_HV_BatCntctrStat_Value, sw-syscond=1}
              IN_VeCCCR_I_ChrgCrntReqDelta_Value: accessed-variable=VeCCCR_I_ChrgCrntReqDelta.Value, variation-point={short-label=vpIN_VeCCCR_I_ChrgCrntReqDelta_Value, sw-syscond=1}
              IN_VeCITR_Cnt_DCEOL_SgnlRcvd_Value: accessed-variable=VeCITR_Cnt_DCEOL_SgnlRcvd.Value, variation-point={short-label=vpIN_VeCITR_Cnt_DCEOL_SgnlRcvd_Value, sw-syscond=1}
              IN_VeCITR_e_DCChrg_TestSts_Value: accessed-variable=VeCITR_e_DCChrg_TestSts.Value, variation-point={short-label=vpIN_VeCITR_e_DCChrg_TestSts_Value, sw-syscond=1}
              IN_VeCPLR_b_Lock_Status_Value: accessed-variable=VeCPLR_b_Lock_Status.Value, variation-point={short-label=vpIN_VeCPLR_b_Lock_Status_Value, sw-syscond=1}
              IN_VeESMR_P_BattLTMaxLim_Value: accessed-variable=VeESMR_P_BattLTMaxLim.Value, variation-point={short-label=vpIN_VeESMR_P_BattLTMaxLim_Value, sw-syscond=1}
              IN_VeHPMR_b_BattCntctrOpenPndg_Value: accessed-variable=VeHPMR_b_BattCntctrOpenPndg.Value, variation-point={short-label=vpIN_VeHPMR_b_BattCntctrOpenPndg_Value, sw-syscond=1}
              IN_VeHVTR_I_HV_AccCurr_Value: accessed-variable=VeHVTR_I_HV_AccCurr.Value, variation-point={short-label=vpIN_VeHVTR_I_HV_AccCurr_Value, sw-syscond=1}
              IN_VeHVTR_I_StringsCurrFdbk_Value: accessed-variable=VeHVTR_I_StringsCurrFdbk.Value, variation-point={short-label=vpIN_VeHVTR_I_StringsCurrFdbk_Value, sw-syscond=1}
              IN_VeHVTR_U_HV_BatVoltModMaxArb_Value: accessed-variable=VeHVTR_U_HV_BatVoltModMaxArb.Value, variation-point={short-label=vpIN_VeHVTR_U_HV_BatVoltModMaxArb_Value, sw-syscond=1}
              IN_VeHVTR_U_HvBattVolt_Arb_Value: accessed-variable=VeHVTR_U_HvBattVolt_Arb.Value, variation-point={short-label=vpIN_VeHVTR_U_HvBattVolt_Arb_Value, sw-syscond=1}
              IN_VeIDCR_I_EVSEMaxCurrLmt_Value: accessed-variable=VeIDCR_I_EVSEMaxCurrLmt.Value, variation-point={short-label=vpIN_VeIDCR_I_EVSEMaxCurrLmt_Value, sw-syscond=1}
              IN_VeIDCR_I_EVSEMinCurrLmt_Value: accessed-variable=VeIDCR_I_EVSEMinCurrLmt.Value, variation-point={short-label=vpIN_VeIDCR_I_EVSEMinCurrLmt_Value, sw-syscond=1}
              IN_VeIDCR_I_EVSEOutputCurr_Value: accessed-variable=VeIDCR_I_EVSEOutputCurr.Value, variation-point={short-label=vpIN_VeIDCR_I_EVSEOutputCurr_Value, sw-syscond=1}
              IN_VeIDCR_K_Service_ID_Value: accessed-variable=VeIDCR_K_Service_ID.Value, variation-point={short-label=vpIN_VeIDCR_K_Service_ID_Value, sw-syscond=1}
              IN_VeIDCR_P_EVSEMaxPwrLmt_Value: accessed-variable=VeIDCR_P_EVSEMaxPwrLmt.Value, variation-point={short-label=vpIN_VeIDCR_P_EVSEMaxPwrLmt_Value, sw-syscond=1}
              IN_VeIDCR_U_EVSEMaxVoltLmt_Value: accessed-variable=VeIDCR_U_EVSEMaxVoltLmt.Value, variation-point={short-label=vpIN_VeIDCR_U_EVSEMaxVoltLmt_Value, sw-syscond=1}
              IN_VeIDCR_U_EVSEOutputVolt_Value: accessed-variable=VeIDCR_U_EVSEOutputVolt.Value, variation-point={short-label=vpIN_VeIDCR_U_EVSEOutputVolt_Value, sw-syscond=1}
              IN_VeIDCR_b_DC_TimeOut_Value: accessed-variable=VeIDCR_b_DC_TimeOut.Value, variation-point={short-label=vpIN_VeIDCR_b_DC_TimeOut_Value, sw-syscond=1}
              IN_VeIDCR_b_EVCC_FailureSts_Value: accessed-variable=VeIDCR_b_EVCC_FailureSts.Value, variation-point={short-label=vpIN_VeIDCR_b_EVCC_FailureSts_Value, sw-syscond=1}
              IN_VeIDCR_b_EVSECurrLmtAchvd_Value: accessed-variable=VeIDCR_b_EVSECurrLmtAchvd.Value, variation-point={short-label=vpIN_VeIDCR_b_EVSECurrLmtAchvd_Value, sw-syscond=1}
              IN_VeIDCR_b_EVSEProcessing_Value: accessed-variable=VeIDCR_b_EVSEProcessing.Value, variation-point={short-label=vpIN_VeIDCR_b_EVSEProcessing_Value, sw-syscond=1}
              IN_VeIDCR_b_EVSEPwrLmtAchvd_Value: accessed-variable=VeIDCR_b_EVSEPwrLmtAchvd.Value, variation-point={short-label=vpIN_VeIDCR_b_EVSEPwrLmtAchvd_Value, sw-syscond=1}
              IN_VeIDCR_b_EVSEVoltLmtAchvd_Value: accessed-variable=VeIDCR_b_EVSEVoltLmtAchvd.Value, variation-point={short-label=vpIN_VeIDCR_b_EVSEVoltLmtAchvd_Value, sw-syscond=1}
              IN_VeIDCR_b_EVSE_FreeService_Value: accessed-variable=VeIDCR_b_EVSE_FreeService.Value, variation-point={short-label=vpIN_VeIDCR_b_EVSE_FreeService_Value, sw-syscond=1}
              IN_VeIDCR_b_EVSE_Offered_DC_Extended_Value: accessed-variable=VeIDCR_b_EVSE_Offered_DC_Extended.Value, variation-point={short-label=vpIN_VeIDCR_b_EVSE_Offered_DC_Extended_Value, sw-syscond=1}
              IN_VeIDCR_b_EVSE_Service1_Charging_Value: accessed-variable=VeIDCR_b_EVSE_Service1_Charging.Value, variation-point={short-label=vpIN_VeIDCR_b_EVSE_Service1_Charging_Value, sw-syscond=1}
              IN_VeIDCR_b_EVSE_Service1_Free_Value: accessed-variable=VeIDCR_b_EVSE_Service1_Free.Value, variation-point={short-label=vpIN_VeIDCR_b_EVSE_Service1_Free_Value, sw-syscond=1}
              IN_VeIDCR_b_EVSEsupported_DIN_Value: accessed-variable=VeIDCR_b_EVSEsupported_DIN.Value, variation-point={short-label=vpIN_VeIDCR_b_EVSEsupported_DIN_Value, sw-syscond=1}
              IN_VeIDCR_b_EVSEsupported_ISO1_Value: accessed-variable=VeIDCR_b_EVSEsupported_ISO1.Value, variation-point={short-label=vpIN_VeIDCR_b_EVSEsupported_ISO1_Value, sw-syscond=1}
              IN_VeIDCR_b_GBT_EVSEChrgPermitting_Value: accessed-variable=VeIDCR_b_GBT_EVSEChrgPermitting.Value, variation-point={short-label=vpIN_VeIDCR_b_GBT_EVSEChrgPermitting_Value, sw-syscond=1}
              IN_VeIDCR_b_IDCM_DCCA_Value: accessed-variable=VeIDCR_b_IDCM_DCCA.Value, variation-point={short-label=vpIN_VeIDCR_b_IDCM_DCCA_Value, sw-syscond=1}
              IN_VeIDCR_b_ISO15118_TLS_Offered_Value: accessed-variable=VeIDCR_b_ISO15118_TLS_Offered.Value, variation-point={short-label=vpIN_VeIDCR_b_ISO15118_TLS_Offered_Value, sw-syscond=1}
              IN_VeIDCR_b_J1772_S2_Status_Value: accessed-variable=VeIDCR_b_J1772_S2_Status.Value, variation-point={short-label=vpIN_VeIDCR_b_J1772_S2_Status_Value, sw-syscond=1}
              IN_VeIDCR_b_OBCM_TimeOut_Value: accessed-variable=VeIDCR_b_OBCM_TimeOut.Value, variation-point={short-label=vpIN_VeIDCR_b_OBCM_TimeOut_Value, sw-syscond=1}
              IN_VeIDCR_b_OfferedPaymentContract_Value: accessed-variable=VeIDCR_b_OfferedPaymentContract.Value, variation-point={short-label=vpIN_VeIDCR_b_OfferedPaymentContract_Value, sw-syscond=1}
              IN_VeIDCR_b_OfferedPaymentEIM_Value: accessed-variable=VeIDCR_b_OfferedPaymentEIM.Value, variation-point={short-label=vpIN_VeIDCR_b_OfferedPaymentEIM_Value, sw-syscond=1}
              IN_VeIDCR_b_PlugAndChargeReq_Value: accessed-variable=VeIDCR_b_PlugAndChargeReq.Value, variation-point={short-label=vpIN_VeIDCR_b_PlugAndChargeReq_Value, sw-syscond=1}
              IN_VeIDCR_b_Service2_Certificate_Value: accessed-variable=VeIDCR_b_Service2_Certificate.Value, variation-point={short-label=vpIN_VeIDCR_b_Service2_Certificate_Value, sw-syscond=1}
              IN_VeIDCR_b_TCPCommTerminated_Value: accessed-variable=VeIDCR_b_TCPCommTerminated.Value, variation-point={short-label=vpIN_VeIDCR_b_TCPCommTerminated_Value, sw-syscond=1}
              IN_VeIDCR_b_TLS_Offered_Value: accessed-variable=VeIDCR_b_TLS_Offered.Value, variation-point={short-label=vpIN_VeIDCR_b_TLS_Offered_Value, sw-syscond=1}
              IN_VeIDCR_b_V2X_EVSE_Service_5_Free_Value: accessed-variable=VeIDCR_b_V2X_EVSE_Service_5_Free.Value, variation-point={short-label=vpIN_VeIDCR_b_V2X_EVSE_Service_5_Free_Value, sw-syscond=1}
              IN_VeIDCR_b_V2X_EVSE_Service_5_V2H_Value: accessed-variable=VeIDCR_b_V2X_EVSE_Service_5_V2H.Value, variation-point={short-label=vpIN_VeIDCR_b_V2X_EVSE_Service_5_V2H_Value, sw-syscond=1}
              IN_VeIDCR_e_Chrgr_FaultStates_Value: accessed-variable=VeIDCR_e_Chrgr_FaultStates.Value, variation-point={short-label=vpIN_VeIDCR_e_Chrgr_FaultStates_Value, sw-syscond=1}
              IN_VeIDCR_e_EVSEIsolSts_Value: accessed-variable=VeIDCR_e_EVSEIsolSts.Value, variation-point={short-label=vpIN_VeIDCR_e_EVSEIsolSts_Value, sw-syscond=1}
              IN_VeIDCR_e_EVSENotification_Value: accessed-variable=VeIDCR_e_EVSENotification.Value, variation-point={short-label=vpIN_VeIDCR_e_EVSENotification_Value, sw-syscond=1}
              IN_VeIDCR_e_EVSEStsCode_Value: accessed-variable=VeIDCR_e_EVSEStsCode.Value, variation-point={short-label=vpIN_VeIDCR_e_EVSEStsCode_Value, sw-syscond=1}
              IN_VeIDCR_e_ISO15118_ResponseCode_Value: accessed-variable=VeIDCR_e_ISO15118_ResponseCode.Value, variation-point={short-label=vpIN_VeIDCR_e_ISO15118_ResponseCode_Value, sw-syscond=1}
              IN_VeIDCR_e_ISO15118_TLS_Status_Value: accessed-variable=VeIDCR_e_ISO15118_TLS_Status.Value, variation-point={short-label=vpIN_VeIDCR_e_ISO15118_TLS_Status_Value, sw-syscond=1}
              IN_VeIDCR_e_OffrdEnrgyTxType_Value: accessed-variable=VeIDCR_e_OffrdEnrgyTxType.Value, variation-point={short-label=vpIN_VeIDCR_e_OffrdEnrgyTxType_Value, sw-syscond=1}
              IN_VeIDCR_e_OffrdPayOptn_Value: accessed-variable=VeIDCR_e_OffrdPayOptn.Value, variation-point={short-label=vpIN_VeIDCR_e_OffrdPayOptn_Value, sw-syscond=1}
              IN_VeIDCR_e_PROXY_Plug_and_Charge_Value: accessed-variable=VeIDCR_e_PROXY_Plug_and_Charge.Value, variation-point={short-label=vpIN_VeIDCR_e_PROXY_Plug_and_Charge_Value, sw-syscond=1}
              IN_VeIDCR_e_Response_Code_Value: accessed-variable=VeIDCR_e_Response_Code.Value, variation-point={short-label=vpIN_VeIDCR_e_Response_Code_Value, sw-syscond=1}
              IN_VeIDCR_e_SDP_Sts_Value: accessed-variable=VeIDCR_e_SDP_Sts.Value, variation-point={short-label=vpIN_VeIDCR_e_SDP_Sts_Value, sw-syscond=1}
              IN_VeIDCR_e_SLACSts_Value: accessed-variable=VeIDCR_e_SLACSts.Value, variation-point={short-label=vpIN_VeIDCR_e_SLACSts_Value, sw-syscond=1}
              IN_VeIDCR_e_TLS_Connection_Value: accessed-variable=VeIDCR_e_TLS_Connection.Value, variation-point={short-label=vpIN_VeIDCR_e_TLS_Connection_Value, sw-syscond=1}
              IN_VeIDCR_e_TxGBTMsgResponse_Value: accessed-variable=VeIDCR_e_TxGBTMsgResponse.Value, variation-point={short-label=vpIN_VeIDCR_e_TxGBTMsgResponse_Value, sw-syscond=1}
              IN_VeIDCR_e_TxMsgRequest_Value: accessed-variable=VeIDCR_e_TxMsgRequest.Value, variation-point={short-label=vpIN_VeIDCR_e_TxMsgRequest_Value, sw-syscond=1}
              IN_VeIDCR_e_TxMsgResponse_Value: accessed-variable=VeIDCR_e_TxMsgResponse.Value, variation-point={short-label=vpIN_VeIDCR_e_TxMsgResponse_Value, sw-syscond=1}
              IN_VeIDCR_t_ISO15118_NotificationMaxDelay_Value: accessed-variable=VeIDCR_t_ISO15118_NotificationMaxDelay.Value, variation-point={short-label=vpIN_VeIDCR_t_ISO15118_NotificationMaxDelay_Value, sw-syscond=1}
              IN_VeOBCR_b_ChargingComplete_Value: accessed-variable=VeOBCR_b_ChargingComplete.Value, variation-point={short-label=vpIN_VeOBCR_b_ChargingComplete_Value, sw-syscond=1}
              IN_VeOBCR_b_EnableChargeDC_Value: accessed-variable=VeOBCR_b_EnableChargeDC.Value, variation-point={short-label=vpIN_VeOBCR_b_EnableChargeDC_Value, sw-syscond=1}
              IN_VeOBCR_b_EnblDC_GBT_Value: accessed-variable=VeOBCR_b_EnblDC_GBT.Value, variation-point={short-label=vpIN_VeOBCR_b_EnblDC_GBT_Value, sw-syscond=1}
              IN_VeOBCR_b_PluggedIn_Value: accessed-variable=VeOBCR_b_PluggedIn.Value, variation-point={short-label=vpIN_VeOBCR_b_PluggedIn_Value, sw-syscond=1}
              IN_VeOBCR_e_ChargeType_Value: accessed-variable=VeOBCR_e_ChargeType.Value, variation-point={short-label=vpIN_VeOBCR_e_ChargeType_Value, sw-syscond=1}
              IN_VeOBCR_e_ChrgSysStat_SF_Value: accessed-variable=VeOBCR_e_ChrgSysStat_SF.Value, variation-point={short-label=vpIN_VeOBCR_e_ChrgSysStat_SF_Value, sw-syscond=1}
              IN_VePLTR_b_InFieldMode_Value: accessed-variable=VePLTR_b_InFieldMode.Value, variation-point={short-label=vpIN_VePLTR_b_InFieldMode_Value, sw-syscond=1}
              IN_VePLTR_e_ShippingMode_Value: accessed-variable=VePLTR_e_ShippingMode.Value, variation-point={short-label=vpIN_VePLTR_e_ShippingMode_Value, sw-syscond=1}
              IN_VeSCPR_b_ChargeReq_Value: accessed-variable=VeSCPR_b_ChargeReq.Value, variation-point={short-label=vpIN_VeSCPR_b_ChargeReq_Value, sw-syscond=1}
              IN_VeVTHR_b_Rdy4shutdown_Value: accessed-variable=VeVTHR_b_Rdy4shutdown.Value, variation-point={short-label=vpIN_VeVTHR_b_Rdy4shutdown_Value, sw-syscond=1}
              IN_VeVTHR_b_V2H_Detected_Value: accessed-variable=VeVTHR_b_V2H_Detected.Value, variation-point={short-label=vpIN_VeVTHR_b_V2H_Detected_Value, sw-syscond=1}
          data-send-points:
            53 x access:
              OUT_AeDCCR_y_DCChrgTestSts_AeDCCR_y_DCChrgTestSts: accessed-variable=AeDCCR_y_DCChrgTestSts.AeDCCR_y_DCChrgTestSts, variation-point={short-label=vpOUT_AeDCCR_y_DCChrgTestSts_AeDCCR_y_DCChrgTestSts, sw-syscond=1}
              OUT_VeDCCR_e_Service_Category_Value: accessed-variable=VeDCCR_e_Service_Category.Value
              OUT_VeDCCR_e_SelEnrgyTxType_Value: accessed-variable=VeDCCR_e_SelEnrgyTxType.Value
              OUT_VeDCCR_b_EVReady_Value: accessed-variable=VeDCCR_b_EVReady.Value
              OUT_VeDCCR_e_HCP_EVErrorCode_Value: accessed-variable=VeDCCR_e_HCP_EVErrorCode.Value
              OUT_VeDCCR_I_EVMax_I_Limit_Value: accessed-variable=VeDCCR_I_EVMax_I_Limit.Value
              OUT_VeDCCR_P_EVMax_P_Limit_Value: accessed-variable=VeDCCR_P_EVMax_P_Limit.Value
              OUT_VeDCCR_U_EVMax_V_Limit_Value: accessed-variable=VeDCCR_U_EVMax_V_Limit.Value
              OUT_VeDCCR_E_EVEnergyCapacity_Value: accessed-variable=VeDCCR_E_EVEnergyCapacity.Value
              OUT_VeDCCR_b_DC_Isolation_Cmd_Value: accessed-variable=VeDCCR_b_DC_Isolation_Cmd.Value
              OUT_VeDCCR_e_DC_CntctrCmd_Value: accessed-variable=VeDCCR_e_DC_CntctrCmd.Value
              OUT_VeDCCR_U_EV_DCTargetVolt_Value: accessed-variable=VeDCCR_U_EV_DCTargetVolt.Value
              OUT_VeDCCR_b_WeldChkComplete_Value: accessed-variable=VeDCCR_b_WeldChkComplete.Value
              OUT_VeDCCR_b_RdyToChrgSt_Value: accessed-variable=VeDCCR_b_RdyToChrgSt.Value
              OUT_VeDCCR_K_SelectedServiceID_Value: accessed-variable=VeDCCR_K_SelectedServiceID.Value
              OUT_VeDCCR_e_SelPayOptn_Value: accessed-variable=VeDCCR_e_SelPayOptn.Value
              OUT_VeDCCR_b_HCP_SessionStpCmd_Value: accessed-variable=VeDCCR_b_HCP_SessionStpCmd.Value
              OUT_VeDCCR_e_DCChrg_TestSts_Value: accessed-variable=VeDCCR_e_DCChrg_TestSts.Value
              OUT_VeDCCR_I_DCChrgEOL_TestCrnt_Value: accessed-variable=VeDCCR_I_DCChrgEOL_TestCrnt.Value
              OUT_VeDCCR_e_DCChrgSysStat_SF_Value: accessed-variable=VeDCCR_e_DCChrgSysStat_SF.Value
              OUT_VeDCCR_b_V2GPilotEnable_Value: accessed-variable=VeDCCR_b_V2GPilotEnable.Value
              OUT_VeDCCR_b_V2G_Perf_Inhibited_Value: accessed-variable=VeDCCR_b_V2G_Perf_Inhibited.Value
              OUT_VeDCCR_e_CellVolt_OOR_Value: accessed-variable=VeDCCR_e_CellVolt_OOR.Value
              OUT_VeDCCR_e_ChrgCurr_OOR_Value: accessed-variable=VeDCCR_e_ChrgCurr_OOR.Value
              OUT_VeDCCR_e_BattTemp_OOR_Value: accessed-variable=VeDCCR_e_BattTemp_OOR.Value
              OUT_VeDCCR_e_SOC_OOR_Value: accessed-variable=VeDCCR_e_SOC_OOR.Value
              OUT_VeDCCR_b_CPIM_Error_Value: accessed-variable=VeDCCR_b_CPIM_Error.Value
              OUT_VeDCCR_b_CPIM_OT_Value: accessed-variable=VeDCCR_b_CPIM_OT.Value
              OUT_VeDCCR_Pct_BattFullSOC_Value: accessed-variable=VeDCCR_Pct_BattFullSOC.Value
              OUT_VeDCCR_b_BattOverVolt_Value: accessed-variable=VeDCCR_b_BattOverVolt.Value
              OUT_VeDCCR_b_BattUnderVolt_Value: accessed-variable=VeDCCR_b_BattUnderVolt.Value
              OUT_VeDCCR_b_DCChrgInitialization_Value: accessed-variable=VeDCCR_b_DCChrgInitialization.Value
              OUT_VeDCCR_b_DCGBTReadyToCharge_Value: accessed-variable=VeDCCR_b_DCGBTReadyToCharge.Value
              OUT_VeDCCR_b_DCGBTEVChrgPermit_Value: accessed-variable=VeDCCR_b_DCGBTEVChrgPermit.Value
              OUT_VeDCCR_T_GBT_MaxBattTempAllwd_Value: accessed-variable=VeDCCR_T_GBT_MaxBattTempAllwd.Value
              OUT_VeDCCR_e_GBT_ChrgCntrolMethod_Value: accessed-variable=VeDCCR_e_GBT_ChrgCntrolMethod.Value
              OUT_VeDCCR_e_GBT_ChrgrInterrupt_Value: accessed-variable=VeDCCR_e_GBT_ChrgrInterrupt.Value
              OUT_VeDCCR_e_SelectAppProtocol_Value: accessed-variable=VeDCCR_e_SelectAppProtocol.Value
              OUT_VeDCCR_b_SelectSecProtocol_Value: accessed-variable=VeDCCR_b_SelectSecProtocol.Value
              OUT_VeDCCR_e_ChargeProgress_Value: accessed-variable=VeDCCR_e_ChargeProgress.Value
              OUT_VeDCCR_e_DC_ChrgTypeCmd_Value: accessed-variable=VeDCCR_e_DC_ChrgTypeCmd.Value
              OUT_VeDCCR_b_J1772_S2_Close_DC_SF_Value: accessed-variable=VeDCCR_b_J1772_S2_Close_DC_SF.Value
              OUT_VeDCCR_k_DCExitRsn_SF_Value: accessed-variable=VeDCCR_k_DCExitRsn_SF.Value
              OUT_VeDCCR_e_DCGBTChrgSysStat_Value: accessed-variable=VeDCCR_e_DCGBTChrgSysStat.Value
              OUT_VeDCCR_b_V2H_MaxCurrPwrLim_NegVal_Value: accessed-variable=VeDCCR_b_V2H_MaxCurrPwrLim_NegVal.Value
              OUT_VeDCCR_b_V2H_SelEnergyTransType_Value: accessed-variable=VeDCCR_b_V2H_SelEnergyTransType.Value
              OUT_VeDCCR_P_V2H_EVMaxPwrLim_Value: accessed-variable=VeDCCR_P_V2H_EVMaxPwrLim.Value
              OUT_VeDCCR_e_Protocol_Priority{1..3}_Value: accessed-variable=VeDCCR_e_Protocol_Priority{1..3}.Value
              OUT_VeDCCR_k_MaxEntriesSASScheduleTuple_Value: accessed-variable=VeDCCR_k_MaxEntriesSASScheduleTuple.Value
              OUT_VeDCCR_b_PnCFailure_Value: accessed-variable=VeDCCR_b_PnCFailure.Value
              OUT_VeDCCR_b_PnCRetryFail_Value: accessed-variable=VeDCCR_b_PnCRetryFail.Value
        DCCR_PwrOff: variation-point={short-label=vpDCCR_PwrOff, sw-syscond=1}
          data-send-points:
            4 x access:
              OUT_EeDCCR_t_V2GPerfInhibTime_EeDCCR_t_V2GPerfInhibTime: accessed-variable=EeDCCR_t_V2GPerfInhibTime.EeDCCR_t_V2GPerfInhibTime, variation-point={short-label=vpOUT_EeDCCR_t_V2GPerfInhibTime_EeDCCR_t_V2GPerfInhibTime, sw-syscond=1}
              OUT_EeDCCR_t_V2GTime_EeDCCR_t_V2GTime: accessed-variable=EeDCCR_t_V2GTime.EeDCCR_t_V2GTime, variation-point={short-label=vpOUT_EeDCCR_t_V2GTime_EeDCCR_t_V2GTime, sw-syscond=1}
              OUT_NeDCCR_E_TECharge_NeDCCR_E_TECharge: accessed-variable=NeDCCR_E_TECharge.NeDCCR_E_TECharge, variation-point={short-label=vpOUT_NeDCCR_E_TECharge_NeDCCR_E_TECharge, sw-syscond=1}
              OUT_NeDCCR_E_TEDischarge_NeDCCR_E_TEDischarge: accessed-variable=NeDCCR_E_TEDischarge.NeDCCR_E_TEDischarge, variation-point={short-label=vpOUT_NeDCCR_E_TEDischarge_NeDCCR_E_TEDischarge, sw-syscond=1}
      variation point proxy Variant_DCCR_1: category=CONDITION, condition-access=1
